# ECAP0_CTL_STS register map
Vendor: Texas Instruments
Peripheral module from a debugger description file (folder am65x).
Registers are 32-bit, read-write, reset 0x0 unless marked. A register's access mark holds for its fields unless they carry their own. Offsets are as the file gives them; lines under a group give offsets from that group; [hi:lo] are bit positions; {n}, {i} and the like mark numbered series; 'fields as' and 'values as' point back to an identical list; <NAME> marks a mode.

## ECAP0_CTL_STS
0x00 ECAP_TSCNT — Time Stamp Counter Register.
  [31:0] TSCNT — Active 32 bit-counter register that is used as the capture time-base
0x04 ECAP_CNTPHS — Counter Phase Control Register.
  [31:0] CNTPHS — Counter phase value register that can be programmed for phase lag/lead. This register shadows TSCNT and is loaded into
0x08 ECAP_CAP1 — Capture-1 Register.
  [31:0] CAP1 — This register can be loaded (written) by the following.
0x0C ECAP_CAP2 — Capture-2 Register.
  [31:0] CAP2 — This register can be loaded (written) by the following.
0x10 ECAP_CAP3 — Capture-3 Register.
  [31:0] CAP3 — In CMP mode, this is a time-stamp capture register. In APWM mode, this is the period shadow (APRD) register. User SW updates the PWM period value through this register. In this mode, CAP3 shadows CAP1.
0x14 ECAP_CAP4 — Capture-4 Register.
  [31:0] CAP4 — In CMP mode, this is a time-stamp capture register. In APWM mode, this is the compare shadow (ACMP) register. User SW updates the PWM compare value through this register. In this mode, CAP4 shadows CAP2.
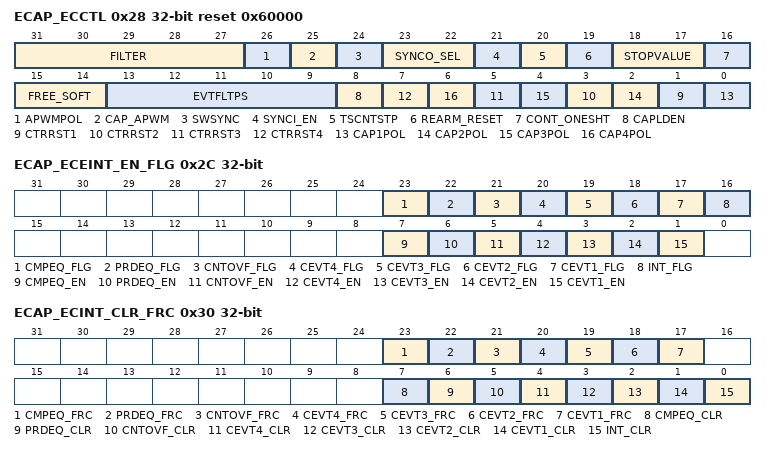
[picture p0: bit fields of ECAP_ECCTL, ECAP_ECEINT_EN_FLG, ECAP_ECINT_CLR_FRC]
0x28 ECAP_ECCTL access per field reset 0x60000 — ECAP Control Register.
  [31:27] FILTER ro
  [26] APWMPOL rw — APWM output polarity select. This is applicable only in APWM operating mode 0h = Output is active high (Compare value defines high time) 1h = Output is active low (Compare value defines low time)
  [25] CAP_APWM rw — CAP/APWM operating mode select 0h = ECAP module operates in capture mode. This mode forces the following configuration. 1. Inhibits TSCNT resets via TSCNT = PRD event. 2. Inhibits shadow loads on ECAP_CAP1 and ECAP_CAP2 registers. 3. Permits user to enable ECAP_CAP1- ECAP_CAP4 register load. (d) ECAP input / APWM output pin operates as a capture input.
  [24] SWSYNC rw — Software-forced Counter (TSCNT) Synchronizing. This provides a convenient software method to synchronize some or all ECAP time bases. In APWM mode, the synchronizing can also be done via the TSCNT = PRD event. Note: Selection TSCNT = PRD is meaningful only in APWM mode. However, you can choose it in CAP mode if you find doing so useful.
  [23:22] SYNCO_SEL rw — SyncOut Select
  [21] SYNCI_EN rw
  [20] TSCNTSTP rw — Time Stamp (TSCNT) Counter Stop (freeze) Control 0h = TSCNT stopped 1h = TSCNT free-running
  [19] REARM_RESET rw — One-Shot Re-Arming Control, that is, wait for stop trigger. Note: The re-arm function is valid in one shot or continuous mode. 0h = Has no effect (reading always returns a 0) 1h = Arms the one-shot sequence as follows: 1) Resets the Mod4 counter to zero. 2) Unfreezes the Mod4 counter. 3) Enables capture register loads.
  [18:17] STOPVALUE rw — Stop value for one-shot mode. This is the number (between 1 and 4) of captures allowed to occur before the CAP (1 through 4) registers are frozen, that is, capture sequence is stopped. Wrap value for continuous mode. This is the number (between 1 and 4) of the capture register in which the circular buffer wraps around and starts again. Notes: STOPVALUE is compared to Mod4 counter and, when equal, the following two actions occur. (1) Mod4 counter is stopped (frozen). (2) Capture register loads are inhibited. In one-shot mode, further interrupt events are blocked until re-armed. 0h = Stop after Capture Event 1 in one-shot mode. Wrap after Capture Event 1 in continuous mode. 1h = Stop after Capture Event 2 in one-shot mode. Wrap after Capture Event 2 in continuous mode. 2h = Stop after Capture Event 3 in one-shot mode. Wrap after Capture Event 3 in continuous mode. 3h = Stop after Capture Event 4 in one-shot mode. Wrap after Capture Event 4 in continuous mode.
  [16] CONT_ONESHT rw — Continuous or one-shot mode control (applicable only in capture mode) 0h = Operate in continuous mode 1h = Operate in one-shot mode
  [15:14] FREE_SOFT rw — Emulation Control
  [13:9] EVTFLTPS rw — Event Filter prescale select:
  [8] CAPLDEN rw — Enable Loading of
  [2n-1] CTRRST{n} rw (n=1..4) — Counter Reset on Capture Event {n}
  [2n-2] CAP{n}POL rw (n=1..4) — Capture Event {n} Polarity select
0x2C ECAP_ECEINT_EN_FLG access per field — ECAP Interrupt Enable and Flag Register.
  [23] CMPEQ_FLG ro — Compare Equal Compare Status Flag. This flag is only active in APWM mode. 0h = Indicates no event occurred 1h = Indicates the counter (TSCNT) reached the compare register value (ACMP)
  [22] PRDEQ_FLG ro — Counter Equal Period Status Flag. This flag is only active in APWM mode. 0h = Indicates no event occurred 1h = Indicates the counter (TSCNT) reached the period register value (APRD) and was reset.
  [21] CNTOVF_FLG ro — Counter Overflow Status Flag. This flag is active in CAP and APWM mode. 0h = Indicates no event occurred. 1h = Indicates the counter (TSCNT) has made the transition from FFFF FFFFh to 0000 0000h
  [20] CEVT4_FLG ro — Capture Event 4 Status Flag. This flag is only active in CAP mode. 0h = Indicates no event occurred 1h = Indicates the fourth event occurred at ECAPn pin
  [19] CEVT3_FLG ro — Capture Event 3 Status Flag. This flag is active only in CAP mode. 0h = Indicates no event occurred. 1h = Indicates the third event occurred at ECAPn pin.
  [18] CEVT2_FLG ro — Capture Event 2 Status Flag. This flag is only active in CAP mode. 0h = Indicates no event occurred. 1h = Indicates the second event occurred at ECAPn pin.
  [17] CEVT1_FLG ro — Capture Event 1 Status Flag. This flag is only active in CAP mode. 0h = Indicates no event occurred. 1h = Indicates the first event occurred at ECAPn pin.
  [16] INT_FLG ro — Global Interrupt Status Flag 0h = Indicates no interrupt generated. 1h = Indicates that an interrupt was generated.
  [7] CMPEQ_EN rw — Counter Equal Compare Interrupt Enable. 0h = Disable Compare Equal as an Interrupt source. 1h = Enable Compare Equal as an Interrupt source.
  [6] PRDEQ_EN rw — Counter Equal Period Interrupt Enable. 0h = Disable Period Equal as an Interrupt source. 1h = Enable Period Equal as an Interrupt source.
  [5] CNTOVF_EN rw — Counter Overflow Interrupt Enable. 0h = Disable counter Overflow as an Interrupt source. 1h = Enable counter Overflow as an Interrupt source.
  [4] CEVT4_EN rw — Capture Event 4 Interrupt Enable. 0h = Disable Capture Event 4 as an Interrupt source. 1h = Enable Capture Event 4 as an Interrupt source.
  [3] CEVT3_EN rw — Capture Event 3 Interrupt Enable. 0h = Disable Capture Event 3 as an Interrupt source. 1h = Enable Capture Event 3 as an Interrupt source.
  [2] CEVT2_EN rw — Capture Event 2 Interrupt Enable. 0h = Disable Capture Event 2 as an Interrupt source. 1h = Enable Capture Event 2 as an Interrupt source.
  [1] CEVT1_EN rw — Capture Event 1 Interrupt Enable . 0h = Disable Capture Event 1 as an Interrupt source. 1h = Enable Capture Event 1 as an Interrupt source.
0x30 ECAP_ECINT_CLR_FRC access not given — ECAP Interrupt Clear and Forcing Register.
  [23] CMPEQ_FRC — Force Counter Equal Compare Interrupt 0h = No effect. Always reads back a 0. 1h = Writing a 1 sets the TSCNT=CMP flag bit. (access RW1S)
  [22] PRDEQ_FRC — Force Counter Equal Period Interrupt 0h = No effect. Always reads back a 0. 1h = Writing a 1 sets the TSCNT=PRD flag bit. (access RW1S)
  [21] CNTOVF_FRC — Force Counter Overflow 0h = No effect. Always reads back a 0. 1h = Writing a 1 to this bit sets the CNTOVF flag bit. (access RW1S)
  [20] CEVT4_FRC — Force Capture Event 4 0h = No effect. Always reads back a 0. 1h = Writing a 1 sets the CEVT4 flag bit (access RW1S)
  [19] CEVT3_FRC — Force Capture Event 3 0h = No effect. Always reads back a 0. 1h = Writing a 1 sets the CEVT3 flag bit (access RW1S)
  [18] CEVT2_FRC — Force Capture Event 2 0h = No effect. Always reads back a 0. 1h = Writing a 1 sets the CEVT2 flag bit. (access RW1S)
  [17] CEVT1_FRC — Force Capture Event 1 0h = No effect. Always reads back a 0. 1h = Writing a 1 sets the CEVT1 flag bit. (access RW1S)
  [7] CMPEQ_CLR — Counter Equal Compare Status Flag 0h = Writing a 0 has no effect. Always reads back a 0 1h = Writing a 1 clears the TSCNT=CMP flag condition (access RW1C)
  [6] PRDEQ_CLR — Counter Equal Period Status Flag 0h = Writing a 0 has no effect. Always reads back a 0 1h = Writing a 1 clears the TSCNT=PRD flag condition (access RW1C)
  [5] CNTOVF_CLR — Counter Overflow Status Flag 0h = Writing a 0 has no effect. Always reads back a 0 1h = Writing a 1 clears the CNTOVF flag condition (access RW1C)
  [4] CEVT4_CLR — Capture Event 4 Status Flag 0h = Writing a 0 has no effect. Always reads back a 0. 1h = Writing a 1 clears the CEVT3 flag condition. (access RW1C)
  [3] CEVT3_CLR — Capture Event 3 Status Flag 0h = Writing a 0 has no effect. Always reads back a 0. 1h = Writing a 1 clears the CEVT3 flag condition. (access RW1C)
  [2] CEVT2_CLR — Capture Event 2 Status Flag 0h = Writing a 0 has no effect. Always reads back a 0. 1h = Writing a 1 clears the CEVT2 flag condition. (access RW1C)
  [1] CEVT1_CLR — Capture Event 1 Status Flag 0h = Writing a 0 has no effect. Always reads back a 0. 1h = Writing a 1 clears the CEVT1 flag condition. (access RW1C)
  [0] INT_CLR — Global Interrupt Clear Flag 0h = Writing a 0 has no effect. Always reads back a 0. 1h = Writing a 1 clears the INT flag and enable further interrupts to be generated if any of the event flags are set to 1. (access RW1C)
0x5C ECAP_PID ro reset 0x44D23900 — ECAP Revision ID.
  [31:0] REVISION — TI internal data. Identifies revision of peripheral.
